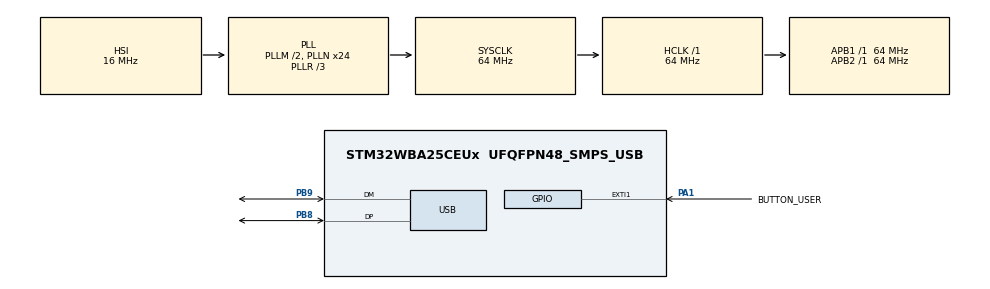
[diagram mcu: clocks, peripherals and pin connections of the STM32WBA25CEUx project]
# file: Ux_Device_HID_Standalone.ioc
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CORTEX_M33_NS.userName=CORTEX_M33
Mcu.Family=STM32WBA
Mcu.Name=STM32WBA25CEUx
Mcu.Package=UFQFPN48_SMPS_USB
NVIC.EXTI1_IRQn=true\:7\:0\:true\:false\:true\:true\:true\:true
NVIC.PriorityGroup=NVIC_PRIORITYGROUP_4
NVIC.USB_DRD_FS_IRQn=true\:6\:0\:true\:false\:true\:true\:true\:true
OSC_IN.Mode=HSE-External-Oscillator
OSC_IN.Signal=RCC_OSC_IN
OSC_OUT.Mode=HSE-External-Oscillator
OSC_OUT.Signal=RCC_OSC_OUT
PA1.GPIO_Label=BUTTON_USER
PA1.GPIO_ModeDefaultEXTI=GPIO_MODE_IT_FALLING
PA1.GPIO_PuPd=GPIO_PULLUP
PA1.Signal=GPXTI1
PB8.Mode=Device
PB8.Signal=USB_DP
PB9.Mode=Device
PB9.Signal=USB_DM
ProjectManager.HeapSize=0x200
ProjectManager.StackSize=0x400
ProjectManager.TargetToolchain=EWARM V9.60
RCC.ADCFreq_Value=64000000
RCC.AHB5CLKDivider=RCC_SYSCLK_PLL1_DIV2
RCC.AHBFreq_Value=64000000
RCC.APB1Freq_Value=64000000
RCC.APB1TimFreq_Value=64000000
RCC.APB2Freq_Value=64000000
RCC.APB2TimFreq_Value=64000000
RCC.CortexFreq_Value=8000000
RCC.HCLKFreq_Value=64000000
RCC.HSE_VALUE=32000000
RCC.HSI_VALUE=16000000
RCC.LSE_VALUE=32768
RCC.PLL1P=4
RCC.PLL1R=3
RCC.PLLFRACN=0
RCC.PLLM=2
RCC.PLLN=24
RCC.SYSCLKFreq_VALUE=64000000
RCC.SYSCLKSourceVirtual=RCC_SYSCLKSOURCE_PLLCLK
RCC.VCOOutputFreq_Value=192000000
USB.VirtualMode=Device_Only
USBX.BSP.number=1
USBX.Core_System=1
USBX.MAX_POWER_IN_MILLI_AMPER=0
USBX.REG_USBX_DEVICE_CON_CK=0
USBX.USBD_COMPOSITE_USE_IAD=0
USBX.USBD_PRODUCT_STRING=STM32 HID Mouse Device
USBX.USBD_SERIAL_NUMBER=HID001
USBX.USBX_SYS_SIZE=1024 * 4
USBX.UX_APP_MEM_POOL_SIZE_STANDALONE=1024 * 4
USBX.UX_DEVICE_DRD_ENABLED_FS=1
USBX.UX_DEVICE_HID_CORE=1
USBX.UX_DEVICE_HID_MOUSE=1
USBX.UX_Device_Controller=1
USBX.UX_Device_CoreStack=1
USBX.UX_SLAVE_REQUEST_DATA_MAX_LENGTH=512
USBX0.BSP.STBoard=false
USBX0.BSP.api=Unknown
USBX0.BSP.instance=USB
USBX0.BSP.ip=USB
USBX0.BSP.mode=Device_Only
USBX0.BSP.name=USB_Device
USBX0.BSP.solution=USB
VP_CORTEX_M33_NS_VS_Hclk.Mode=Hclk_Mode
VP_ICACHE_VS_ICACHE.Mode=DirectMappedCache
VP_PWR_VS_SECSignals.Mode=Security/Privilege
VP_USBX_Core_System.Mode=Core_System
VP_USBX_UX\ Device\ Controller_FS.Mode=UX_Device_Controller_FS
VP_USBX_UX\ Device\ CoreStack_FS.Mode=UX_Device_CoreStack_HS
VP_USBX_UX\ Device\ HID_CORE_FS.Mode=UX_Device_class_HID_CORE_FS
VP_USBX_UX\ Device\ HID_MOUSE_FS.Mode=UX_Device_class_HID_MOUSE_FS
board=custom

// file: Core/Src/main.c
/* USER CODE BEGIN Header */
/**
  ******************************************************************************
  * @file           : main.c
  * @brief          : Main program body
  ******************************************************************************
  * @attention
  *
  * Copyright (c) 2026 STMicroelectronics.
  * All rights reserved.
  *
  * This software is licensed under terms that can be found in the LICENSE file
  * in the root directory of this software component.
  * If no LICENSE file comes with this software, it is provided AS-IS.
  *
  ******************************************************************************
  */
/* USER CODE END Header */
#include "main.h"
#include "app_usbx.h"

PCD_HandleTypeDef hpcd_USB_DRD_FS;

void SystemClock_Config(void);
static void MX_GPIO_Init(void);
static void MX_ICACHE_Init(void);

int main(void)
{

  /* MCU Configuration--------------------------------------------------------*/

  /* Reset of all peripherals, Initializes the Flash interface and the Systick. */
  HAL_Init();

  /* Configure the system clock */
  SystemClock_Config();

  /* Initialize all configured peripherals */
  MX_GPIO_Init();
  MX_ICACHE_Init();
  MX_USBX_Init();

  /* Infinite loop */
  while (1)
  {

    /* USER CODE BEGIN 3 */
    USBX_Device_Process(NULL);
  }
  /* USER CODE END 3 */
}

void SystemClock_Config(void)
{
  RCC_OscInitTypeDef RCC_OscInitStruct = {0};
  RCC_ClkInitTypeDef RCC_ClkInitStruct = {0};

  /** Supply configuration update enable
  */
  HAL_PWREx_ConfigSupply(PWR_LDO_SUPPLY);

  /** Configure the main internal regulator output voltage
  */
  if (HAL_PWREx_ControlVoltageScaling(PWR_REGULATOR_VOLTAGE_SCALE1) != HAL_OK)
  {
    Error_Handler();
  }

  /** Initializes the CPU, AHB and APB busses clocks
  */
  RCC_OscInitStruct.OscillatorType = RCC_OSCILLATORTYPE_HSI;
  RCC_OscInitStruct.HSIState = RCC_HSI_ON;
  RCC_OscInitStruct.HSICalibrationValue = RCC_HSICALIBRATION_DEFAULT;
  RCC_OscInitStruct.PLL1.PLLState = RCC_PLL_ON;
  RCC_OscInitStruct.PLL1.PLLSource = RCC_PLLSOURCE_HSI;
  RCC_OscInitStruct.PLL1.PLLM = 2;
  RCC_OscInitStruct.PLL1.PLLN = 24;
  RCC_OscInitStruct.PLL1.PLLP = 4;
  RCC_OscInitStruct.PLL1.PLLQ = 2;
  RCC_OscInitStruct.PLL1.PLLR = 3;
  RCC_OscInitStruct.PLL1.PLLFractional = 0;
  if (HAL_RCC_OscConfig(&RCC_OscInitStruct) != HAL_OK)
  {
    Error_Handler();
  }

  __HAL_RCC_PLL1CLKOUT_ENABLE(RCC_PLL1_PCLK);

  /** Initializes the CPU, AHB and APB busses clocks
  */
  RCC_ClkInitStruct.ClockType = RCC_CLOCKTYPE_HCLK|RCC_CLOCKTYPE_SYSCLK
                              |RCC_CLOCKTYPE_PCLK1|RCC_CLOCKTYPE_PCLK2
                              |RCC_CLOCKTYPE_PCLK7|RCC_CLOCKTYPE_HCLK5;
  RCC_ClkInitStruct.SYSCLKSource = RCC_SYSCLKSOURCE_PLLCLK;
  RCC_ClkInitStruct.AHBCLKDivider = RCC_SYSCLK_DIV1;
  RCC_ClkInitStruct.APB1CLKDivider = RCC_HCLK_DIV1;
  RCC_ClkInitStruct.APB2CLKDivider = RCC_HCLK_DIV1;
  RCC_ClkInitStruct.APB7CLKDivider = RCC_HCLK_DIV1;
  RCC_ClkInitStruct.AHB5_PLL1_CLKDivider = RCC_SYSCLK_PLL1_DIV2;
  RCC_ClkInitStruct.AHB5_HSEHSI_CLKDivider = RCC_SYSCLK_HSEHSI_DIV1;

  if (HAL_RCC_ClockConfig(&RCC_ClkInitStruct, FLASH_LATENCY_1) != HAL_OK)
  {
    Error_Handler();
  }
}

static void MX_ICACHE_Init(void)
{

  /** Enable instruction cache in 1-way (direct mapped cache)
  */
  if (HAL_ICACHE_ConfigAssociativityMode(ICACHE_1WAY) != HAL_OK)
  {
    Error_Handler();
  }
  if (HAL_ICACHE_Enable() != HAL_OK)
  {
    Error_Handler();
  }

}

void MX_USB_PCD_Init(void)
{

  hpcd_USB_DRD_FS.Instance = USB_DRD_FS;
  hpcd_USB_DRD_FS.Init.dev_endpoints = 8;
  hpcd_USB_DRD_FS.Init.speed = USBD_FS_SPEED;
  hpcd_USB_DRD_FS.Init.phy_itface = PCD_PHY_EMBEDDED;
  hpcd_USB_DRD_FS.Init.Sof_enable = DISABLE;
  hpcd_USB_DRD_FS.Init.low_power_enable = DISABLE;
  hpcd_USB_DRD_FS.Init.lpm_enable = DISABLE;
  hpcd_USB_DRD_FS.Init.battery_charging_enable = DISABLE;
  hpcd_USB_DRD_FS.Init.vbus_sensing_enable = DISABLE;
  hpcd_USB_DRD_FS.Init.bulk_doublebuffer_enable = DISABLE;
  hpcd_USB_DRD_FS.Init.iso_singlebuffer_enable = DISABLE;
  if (HAL_PCD_Init(&hpcd_USB_DRD_FS) != HAL_OK)
  {
    Error_Handler();
  }
  /* USER CODE BEGIN USB_Init 2 */
  HAL_PCDEx_PMAConfig(&hpcd_USB_DRD_FS,  0x00, PCD_SNG_BUF, 0xC0);
  HAL_PCDEx_PMAConfig(&hpcd_USB_DRD_FS,  0x80, PCD_SNG_BUF, 0x100);
  HAL_PCDEx_PMAConfig(&hpcd_USB_DRD_FS,  0x83, PCD_SNG_BUF, 0x140);
  /* USER CODE END USB_Init 2 */

}

static void MX_GPIO_Init(void)
{
  GPIO_InitTypeDef GPIO_InitStruct = {0};

  /* GPIO Ports Clock Enable */
  __HAL_RCC_GPIOA_CLK_ENABLE();
  __HAL_RCC_GPIOB_CLK_ENABLE();

  /*Configure GPIO pin : BUTTON_USER_Pin */
  GPIO_InitStruct.Pin = BUTTON_USER_Pin;
  GPIO_InitStruct.Mode = GPIO_MODE_IT_FALLING;
  GPIO_InitStruct.Pull = GPIO_PULLUP;
  HAL_GPIO_Init(BUTTON_USER_GPIO_Port, &GPIO_InitStruct);

  /* EXTI interrupt init*/
  HAL_NVIC_SetPriority(BUTTON_USER_EXTI_IRQn, 7, 0);
  HAL_NVIC_EnableIRQ(BUTTON_USER_EXTI_IRQn);

}

void Error_Handler(void)
{
  while (1)
  {
  }
}
#ifdef USE_FULL_ASSERT
/**
  * @brief  Reports the name of the source file and the source line number
  *         where the assert_param error has occurred.
  * @param  file: pointer to the source file name
  * @param  line: assert_param error line source number
  * @retval None
  */
void assert_failed(uint8_t *file, uint32_t line)
{
  /* USER CODE BEGIN 6 */
  /* User can add his own implementation to report the file name and line number,
     ex: printf("Wrong parameters value: file %s on line %d\r\n", file, line) */
  /*Infinite loop */
  while (1)
  {
  }
  /* USER CODE END 6 */
}
#endif /* USE_FULL_ASSERT */
